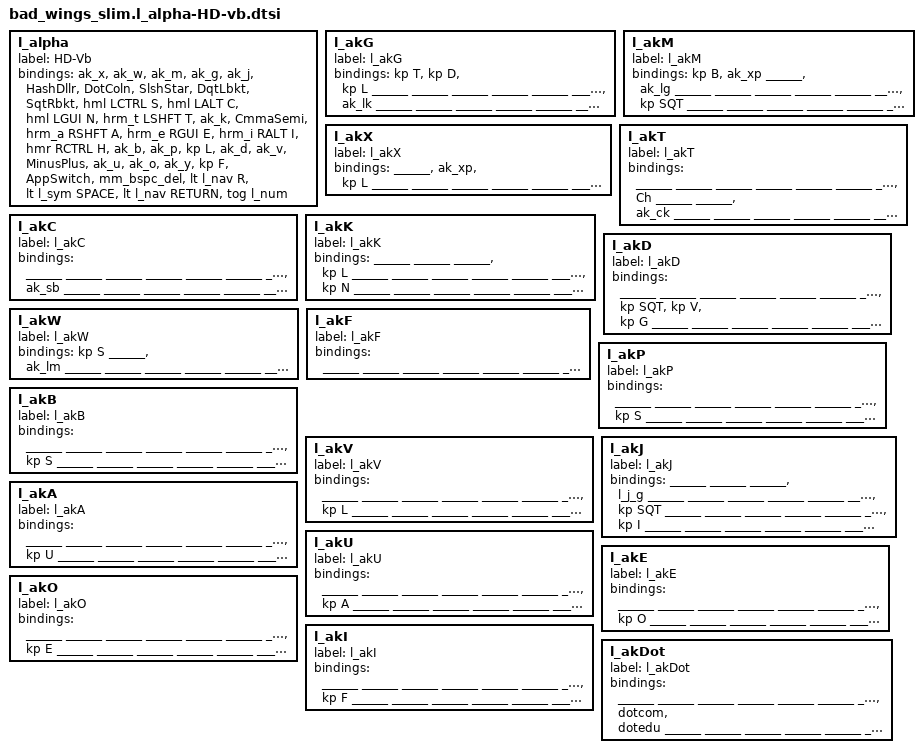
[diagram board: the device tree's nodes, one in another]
#define ______  &trans

/*    KEY POSITION Numbers for Zaphod
 ╭────────────────────╮ ╭────────────────────╮
 │  0   1   2   3   4 │ │  5   6   7   8   9 │
 │ 10  11  12  13  14 │ │ 15  16  17  18  19 |
 | 20  21  22  23  24 │ │ 25  26  27  28  29 |
 ╰───────────╮ 30  31 | | 32  33  ╭──────────╯
             ╰────────╯ ╰─────────╯
*/
/*    KEY POSITION Names
╭─────────────────────╮ ╭─────────────────────╮
│ LT4 LT3 LT2 LT1 LT0 │ │ RT0 RT1 RT2 RT3 RT4 │
│ LM4 LM3 LM2 LM1 LM0 │ │ RM0 RM1 RM2 RM3 RM4 │
│ LB4 LB3 LB2 LB1 LB0 │ │ RB0 RB1 RB2 RB3 RB4 │
╰───────╮ LH3 LH2 LH1 | | RH1 RH2 RH3 ╭───────╯
        ╰─────────────╯ ╰─────────────╯
*/
/*  Base (alpha) Layer  Hands Down Vibranium-vb
        Building for a 34 key board
╭─────────────────────╮ ╭──────────────────────╮
│  X   W   M   G   J  │ │  #$  .:  /*  "[  ']  │
│  S   C   N   T   K  | |  ,;   A   E   I   H  │
│  B   P   L   D   V  │ │  -+   U   O   Y   F  │
╰──────╮  App BSP  R  │ │  SPC RET  TAB ╭──────╯
       ╰──────────────╯ ╰───────────────╯
*/

                l_alpha {
                        label = "HD-Vb";
                        bindings = <

&ak_x   &ak_w   &ak_m     &ak_g     &ak_j              &HashDllr     &DotColn    &SlshStar   &DqtLbkt   &SqtRbkt
&hml LCTRL S &hml LALT C   &hml LGUI N  &hrm_t LSHFT T &ak_k    &CmmaSemi  &hrm_a RSHFT A &hrm_e RGUI E  &hrm_i RALT I  &hmr RCTRL H
&ak_b   &ak_p   &kp L     &ak_d     &ak_v                 &MinusPlus    &ak_u       &ak_o       &ak_y      &kp F


          &AppSwitch &mm_bspc_del &lt l_nav R      &lt l_sym SPACE &lt l_nav RETURN &tog l_num
                        >;
                };

                   l_akG {
                            label = "l_akG";
                            bindings = <
&kp T    &kp D    &kp L    ______   ______       ______   ______   ______   ______   ______
______   ______   ______   ______   &ak_lk       ______   ______   ______   ______   ______
______   ______   ______   ______   ______       ______   ______   ______   ______   ______
                  ______   ______   ______       ______   ______   ______
                            >;
                   };
                   l_akM {
                            label = "l_akM";
                            bindings = <
&kp B    &ak_xp   ______   &ak_lg   ______       ______   ______   ______   ______   ______
______   ______   ______   ______   ______       ______   ______   ______   ______   &kp SQT
______   ______   ______   ______   ______       ______   ______   ______   ______   ______
                  ______   ______   ______       ______   ______   ______
                            >;
                   };
                   l_akX {
                            label = "l_akX";
                            bindings = <
______   &ak_xp   &kp L    ______   ______       ______   ______   ______   ______   ______
______   ______   ______   ______   ______       ______   ______   ______   ______   ______
______   ______   ______   ______   ______       ______   ______   ______   ______   ______
                  ______   ______   ______       ______   ______   ______
                            >;
                   };
                   l_akT {
                            label = "l_akT";
                            bindings = <
______   ______   ______   ______   ______       ______   ______   ______   ______   ______
______   &Ch      ______   ______   &ak_ck       ______   ______   ______   ______   ______
______   ______   ______   ______   ______       ______   ______   ______   ______   ______
                  ______   ______   ______       ______   ______   ______
                            >;
                   };
                   l_akC {
                            label = "l_akC";
                            bindings = <
______   ______   ______   ______   ______       ______   ______   ______   ______   ______
______   ______   ______   ______   ______       ______   ______   ______   ______   ______
&ak_sb   ______   ______   ______   ______       ______   ______   ______   ______   ______
                  ______   ______   ______       ______   ______   ______
                            >;
                   };
                   l_akK {
                            label = "l_akK";
                            bindings = <
______   ______   ______   &kp L    ______       ______   ______   ______   ______   ______
______   ______   ______   &kp N    ______       ______   ______   ______   ______   ______
______   ______   ______   ______   ______       ______   ______   ______   ______   ______
                  ______   ______   ______       ______   ______   ______
                            >;
                   };
                   l_akD {
                            label = "l_akD";
                            bindings = <
______   ______   ______   ______   ______       ______   ______   ______   ______   ______
______   ______   ______   ______   ______       ______   ______   ______   ______   &kp SQT
&kp V    &kp G    ______   ______   ______       ______   ______   ______   ______   ______
                  ______   ______   ______       ______   ______   ______
                            >;
                   };
                   l_akW {
                            label = "l_akW";
                            bindings = <
&kp S    ______   &ak_lm   ______   ______       ______   ______   ______   ______   ______
______   ______   ______   ______   ______       ______   ______   ______   ______   ______
______   ______   ______   ______   ______       ______   ______   ______   ______   ______
                  ______   ______   ______       ______   ______   ______
                            >;
                   };
                   l_akF {
                            label = "l_akF";
                            bindings = <
______   ______   ______   ______   ______       ______   ______   ______   ______   ______
______   ______   ______   ______   ______       ______   ______   ______   ______   ______
______   ______   ______   ______   ______       ______   ______   ______   ______   ______
                  ______   ______   ______       ______   ______   ______
                            >;
                   };
                   l_akP {
                        label = "l_akP";
                        bindings = <

______   ______   ______   ______   ______       ______   ______   ______   ______   ______
______   ______   ______   ______   ______       ______   ______   ______   ______   ______
&kp S    ______   ______   ______   ______       ______   ______   ______   ______   ______
                  ______   ______   ______       ______   ______   ______
                        >;
                   };
                   l_akB {
                            label = "l_akB";
                            bindings = <
______   ______   ______   ______   ______       ______   ______   ______   ______   ______
______   ______   ______   ______   ______       ______   ______   ______   ______   ______
______   &kp S    ______   ______   ______       ______   ______   ______   ______   ______
                  ______   ______   ______       ______   ______   ______
                            >;
                   };
                   l_akV {
                            label = "l_akV";
                            bindings = <
______   ______   ______   ______   ______       ______   ______   ______   ______   ______
______   ______   ______   ______   ______       ______   ______   ______   ______   ______
______   ______   ______   &kp L    ______       ______   ______   ______   ______   ______
                  ______   ______   ______       ______   ______   ______
                            >;
                   };
                   l_akJ {
                            label = "l_akJ";
                            bindings = <
______   ______   ______   &l_j_g   ______       ______   ______   ______   ______   ______
______   ______   ______   ______   ______       ______   ______   ______   ______   &kp SQT
______   ______   ______   ______   ______       ______   ______   ______   ______   &kp I
                  ______   ______   ______       ______   ______   ______
                            >;
                   };

                   l_akA {
                            label = "l_akA";
                            bindings = <
______   ______   ______   ______   ______       ______   ______   ______   ______   ______
______   ______   ______   ______   ______       ______   ______   ______   ______   &kp U
______   ______   ______   ______   ______       ______   ______   ______   ______   ______
                  ______   ______   ______       ______   ______   ______
                            >;
                   };
                   l_akU {
                            label = "l_akU";
                            bindings = <
______   ______   ______   ______   ______       ______   ______   ______   ______   ______
______   ______   ______   ______   ______       ______   ______   ______   ______   &kp A
______   ______   ______   ______   ______       ______   ______   ______   ______   ______
                  ______   ______   ______       ______   ______   ______
                            >;
                   };
                   l_akE {
                            label = "l_akE";
                            bindings = <
______   ______   ______   ______   ______       ______   ______   ______   ______   ______
______   ______   ______   ______   ______       ______   ______   ______   ______   &kp O
______   ______   ______   ______   ______       ______   ______   ______   ______   ______
                  ______   ______   ______       ______   ______   ______
                            >;
                   };
                   l_akO {
                            label = "l_akO";
                            bindings = <
______   ______   ______   ______   ______       ______   ______   ______   ______   ______
______   ______   ______   ______   ______       ______   ______   ______   ______   &kp E
______   ______   ______   ______   ______       ______   ______   ______   ______   ______
                  ______   ______   ______       ______   ______   ______
                            >;
                   };
                   l_akI {
                            label = "l_akI";
                            bindings = <
______   ______   ______   ______   ______       ______   ______   ______   ______   ______
______   ______   ______   ______   ______       ______   ______   ______   ______   &kp F
______   ______   ______   ______   ______       ______   ______   ______   ______   ______
                  ______   ______   ______       ______   ______   ______
                            >;
                   };

                   l_akDot {
                            label = "l_akDot";
                            bindings = <
______   ______   ______   ______   ______       ______   ______   &dotcom  &dotedu  ______
______   ______   ______   ______   ______       ______   ______   ______   ______   ______
______   ______   ______   ______   ______       ______   ______   ______   ______   ______
                  ______   ______   ______       ______   ______   ______
                            >;
                   };
